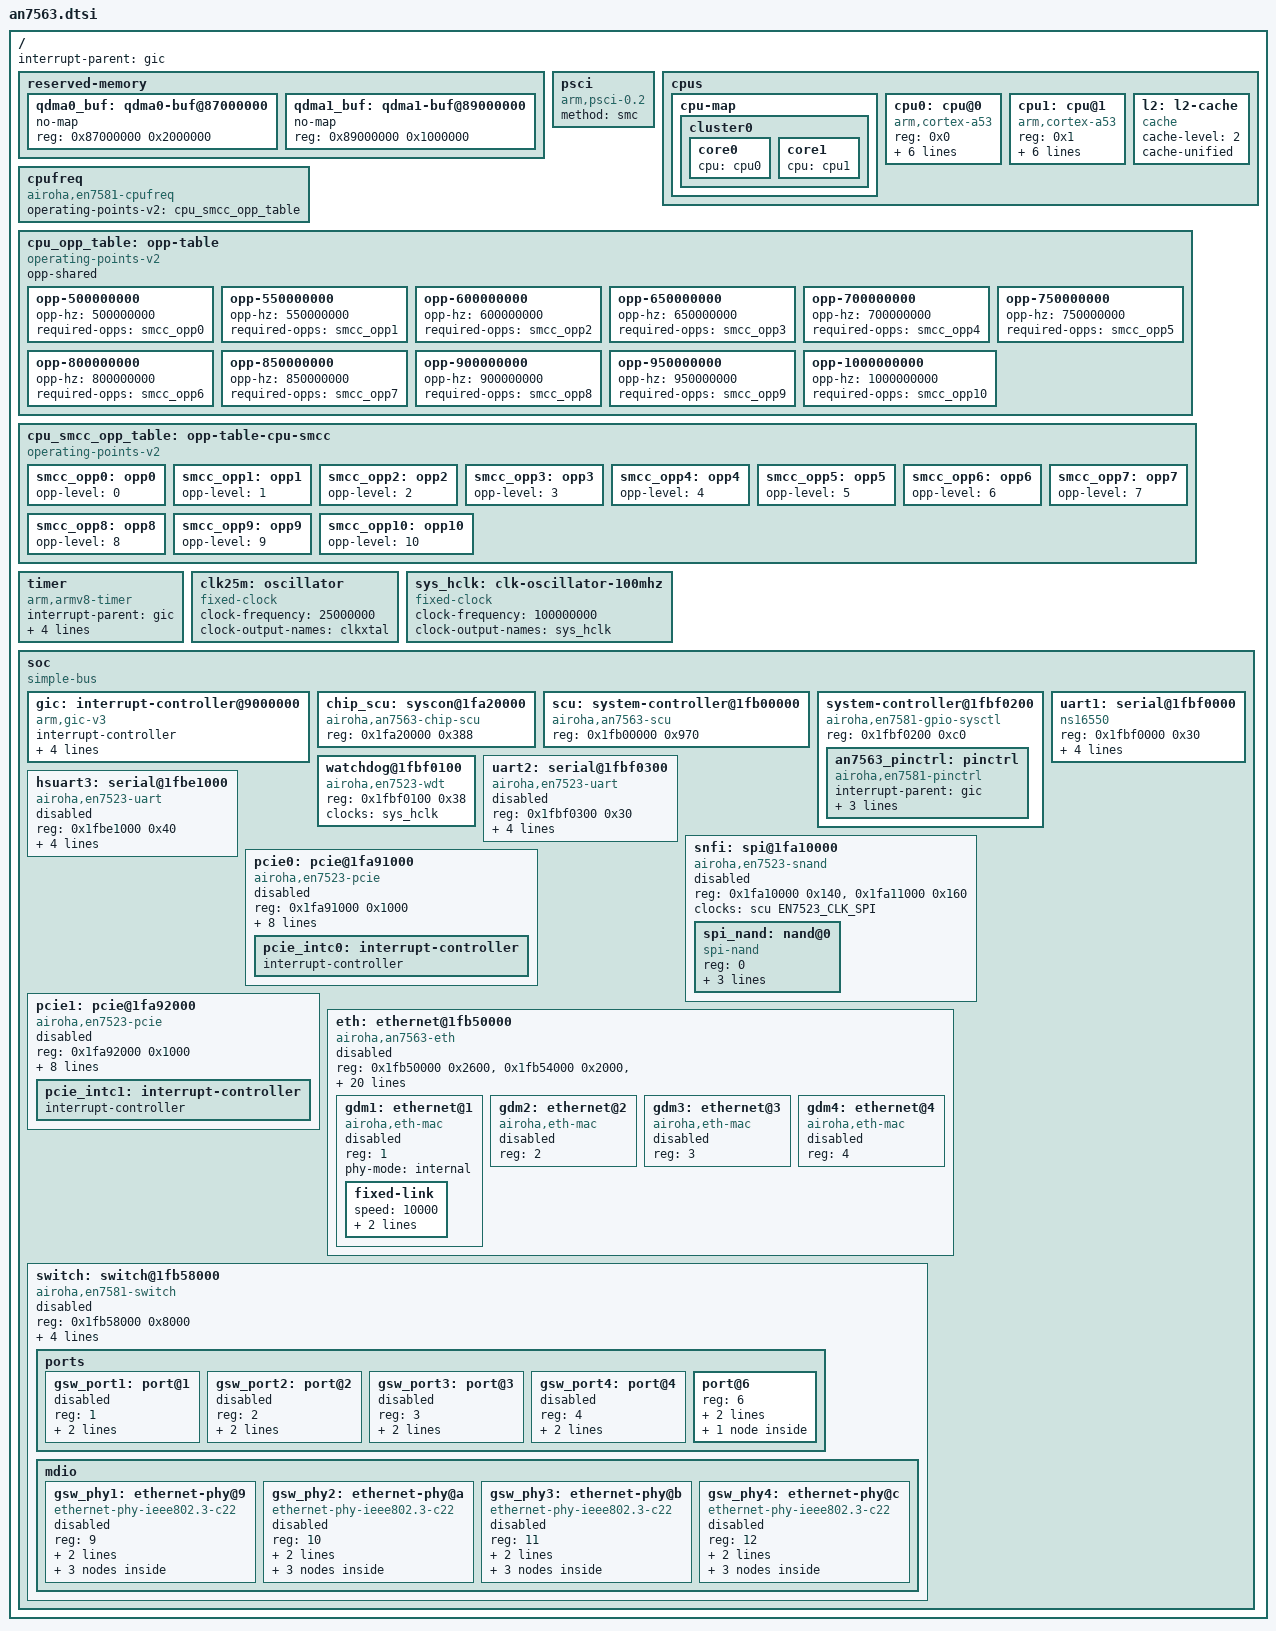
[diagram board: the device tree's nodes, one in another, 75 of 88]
// SPDX-License-Identifier: (GPL-2.0-only OR BSD-2-Clause)
/*
 * Airoha AN7563 / AN7552 SoC dtsi.
 *
 * AN7563 boots a dual Cortex-A53 cluster in 32-bit AArch32 mode, but
 * its chip-SCU and SCU register windows match the EN7581 layout (the
 * IOMUX_1 register sits at chip-SCU offset 0x214, not 0x210 as on
 * EN7523). To share clk-en7523 / reset / pinctrl-airoha driver paths
 * with EN7581, the SCU nodes carry an AN7563-specific compatible
 * followed by the "airoha,en7581-{chip-,}scu" fallback compatible.
 *
 * Naming caveat: vendor device-tree drops (e.g. Xiaomi BE5000's
 * en7563pt_xiaomi-be5000.dts and Netgear EXS27/EXS25/EXS18 GPL
 * en7523.dtsi) tag the root node with "econet,en7523" or
 * "airoha,en7523". That is a vendor naming artefact - the underlying
 * silicon is the EN7581 family (AN7563 is the 2-core AArch32 SKU of
 * the EN7581 IP set), and the Frame Engine / QDMA / GSW / SerDes /
 * chip-SCU register banks all match the EN7581 mainline definitions
 * verified against drivers/net/ethernet/airoha/airoha_eth.c and
 * drivers/clk/clk-en7523.c. Do NOT treat the vendor "en7523"
 * compatible as meaning "EN7523 family" - it does not.
 *
 * Verified against vendor DTS sources:
 *   - Netgear EXS27 V1.0.1.34 GPL drop (target/linux/airoha/files/
 *     arch/arm64/boot/dts/en7523.dtsi)
 *   - Xiaomi BE5000 official DTS (en7563pt_xiaomi-be5000.dts in
 *     the IOWRT Airoha collection drop)
 * Confirmed identical for: frame_engine reg / IRQs (SPI 37/55-57,
 * 38/58-60, 49, 64), GSW reg / IRQ (1fb58000 / SPI 31), chip-SCU
 * IOMUX layout (0x214..0x22C + 0x20C + 0x4C). Only the NPU sub-block
 * differs - AN7563 wires fewer IRQs than EN7581 (9 vs 15) and exposes
 * the extra 0x1e800000+0x60000 SRAM window, so the NPU node is
 * intentionally not declared here until airoha_npu gains AN7563
 * support (NPU_NUM_CORES is currently hardcoded 8).
 */

#include <dt-bindings/interrupt-controller/irq.h>
#include <dt-bindings/interrupt-controller/arm-gic.h>
#include <dt-bindings/clock/en7523-clk.h>
#include <dt-bindings/reset/airoha,en7581-reset.h>
#include <dt-bindings/leds/common.h>

/ {
	interrupt-parent = <&gic>;
	#address-cells = <1>;
	#size-cells = <1>;

	/*
	 * Reserve QDMA0 / QDMA1 hwfd buffer pools at fixed physical
	 * addresses so the airoha_eth driver can map them via
	 * memory-region. Vendor BL2/BL31 reserves the first 0x88000 of
	 * DRAM (see arch/arm/Makefile textofs=0x00088000); board DTS
	 * may further extend reserved-memory if a NPU firmware area or
	 * dying-gasp save region is added.
	 */
	reserved-memory {
		#address-cells = <1>;
		#size-cells = <1>;
		ranges;

		qdma0_buf: qdma0-buf@87000000 {
			no-map;
			reg = <0x87000000 0x2000000>;
		};

		qdma1_buf: qdma1-buf@89000000 {
			no-map;
			reg = <0x89000000 0x1000000>;
		};
	};

	psci {
		compatible = "arm,psci-0.2";
		method = "smc";
	};

	cpus {
		#address-cells = <1>;
		#size-cells = <0>;

		cpu-map {
			cluster0 {
				core0 {
					cpu = <&cpu0>;
				};

				core1 {
					cpu = <&cpu1>;
				};
			};
		};

		cpu0: cpu@0 {
			device_type = "cpu";
			compatible = "arm,cortex-a53";
			reg = <0x0>;
			enable-method = "psci";
			clock-frequency = <80000000>;
			next-level-cache = <&l2>;

			/*
			 * CPUFreq is driven by the airoha,en7581-cpufreq node
			 * below: ATF exposes an SMCCC AVS API which the
			 * airoha-cpu-pmdomain driver wraps as a PM domain +
			 * read-only clock; airoha-cpufreq then registers a
			 * cpufreq-dt device that walks the OPP v2 table.
			 */
			operating-points-v2 = <&cpu_opp_table>;
			clocks = <&cpufreq>;
			clock-names = "cpu";
			power-domains = <&cpufreq>;
			power-domain-names = "perf";
			#cooling-cells = <2>;
		};

		cpu1: cpu@1 {
			device_type = "cpu";
			compatible = "arm,cortex-a53";
			reg = <0x1>;
			enable-method = "psci";
			clock-frequency = <80000000>;
			next-level-cache = <&l2>;

			operating-points-v2 = <&cpu_opp_table>;
			clocks = <&cpufreq>;
			clock-names = "cpu";
			power-domains = <&cpufreq>;
			power-domain-names = "perf";
			#cooling-cells = <2>;
		};

		l2: l2-cache {
			compatible = "cache";
			cache-level = <2>;
			cache-unified;
		};
	};

	/*
	 * CPUFreq plumbing for AN7563. The driver model is the same
	 * one Lorenzo / Christian introduced for EN7581 in
	 * drivers/cpufreq/airoha-cpufreq.c + drivers/pmdomain/mediatek/
	 * airoha-cpu-pmdomain.c. AN7563 ATF exposes the same AVS_OP
	 * SMC handle (0x82000301, AIROHA_AVS_OP_FREQ_DYN_ADJ /
	 * AIROHA_AVS_OP_GET_FREQ), so the same compatible value works.
	 *
	 * Frequency / performance-level pairing is taken from the
	 * Xiaomi BE5000 vendor DTS (en7563pt_xiaomi-be5000.dts), which
	 * lists 500..1000 MHz in 50 MHz steps. AN7563 (AN7552 CPU SKU)
	 * does not expose the 1050..1200 MHz tier that EN7581's larger
	 * 4-core cluster supports, so the OPP table is truncated at
	 * level 10 to match silicon reality - boosting beyond that
	 * would otherwise cause the ATF AVS_OP_FREQ_DYN_ADJ SMC to
	 * silently clip and confuse the OPP framework.
	 */
	cpufreq: cpufreq {
		compatible = "airoha,en7581-cpufreq";

		operating-points-v2 = <&cpu_smcc_opp_table>;

		#power-domain-cells = <0>;
		#clock-cells = <0>;
	};

	cpu_opp_table: opp-table {
		compatible = "operating-points-v2";
		opp-shared;

		opp-500000000 {
			opp-hz = /bits/ 64 <500000000>;
			required-opps = <&smcc_opp0>;
		};

		opp-550000000 {
			opp-hz = /bits/ 64 <550000000>;
			required-opps = <&smcc_opp1>;
		};

		opp-600000000 {
			opp-hz = /bits/ 64 <600000000>;
			required-opps = <&smcc_opp2>;
		};

		opp-650000000 {
			opp-hz = /bits/ 64 <650000000>;
			required-opps = <&smcc_opp3>;
		};

		opp-700000000 {
			opp-hz = /bits/ 64 <700000000>;
			required-opps = <&smcc_opp4>;
		};

		opp-750000000 {
			opp-hz = /bits/ 64 <750000000>;
			required-opps = <&smcc_opp5>;
		};

		opp-800000000 {
			opp-hz = /bits/ 64 <800000000>;
			required-opps = <&smcc_opp6>;
		};

		opp-850000000 {
			opp-hz = /bits/ 64 <850000000>;
			required-opps = <&smcc_opp7>;
		};

		opp-900000000 {
			opp-hz = /bits/ 64 <900000000>;
			required-opps = <&smcc_opp8>;
		};

		opp-950000000 {
			opp-hz = /bits/ 64 <950000000>;
			required-opps = <&smcc_opp9>;
		};

		opp-1000000000 {
			opp-hz = /bits/ 64 <1000000000>;
			required-opps = <&smcc_opp10>;
		};
	};

	cpu_smcc_opp_table: opp-table-cpu-smcc {
		compatible = "operating-points-v2";

		smcc_opp0: opp0 {
			opp-level = <0>;
		};

		smcc_opp1: opp1 {
			opp-level = <1>;
		};

		smcc_opp2: opp2 {
			opp-level = <2>;
		};

		smcc_opp3: opp3 {
			opp-level = <3>;
		};

		smcc_opp4: opp4 {
			opp-level = <4>;
		};

		smcc_opp5: opp5 {
			opp-level = <5>;
		};

		smcc_opp6: opp6 {
			opp-level = <6>;
		};

		smcc_opp7: opp7 {
			opp-level = <7>;
		};

		smcc_opp8: opp8 {
			opp-level = <8>;
		};

		smcc_opp9: opp9 {
			opp-level = <9>;
		};

		smcc_opp10: opp10 {
			opp-level = <10>;
		};
	};

	timer {
		compatible = "arm,armv8-timer";
		interrupt-parent = <&gic>;
		interrupts = <GIC_PPI 13 IRQ_TYPE_LEVEL_LOW>,
			     <GIC_PPI 14 IRQ_TYPE_LEVEL_LOW>,
			     <GIC_PPI 11 IRQ_TYPE_LEVEL_LOW>,
			     <GIC_PPI 10 IRQ_TYPE_LEVEL_LOW>;
	};

	clk25m: oscillator {
		compatible = "fixed-clock";
		#clock-cells = <0>;
		clock-frequency = <25000000>;
		clock-output-names = "clkxtal";
	};

	sys_hclk: clk-oscillator-100mhz {
		compatible = "fixed-clock";
		#clock-cells = <0>;
		clock-frequency = <100000000>;
		clock-output-names = "sys_hclk";
	};

	soc {
		compatible = "simple-bus";
		#address-cells = <1>;
		#size-cells = <1>;
		ranges;

		gic: interrupt-controller@9000000 {
			compatible = "arm,gic-v3";
			interrupt-controller;
			#interrupt-cells = <3>;
			#address-cells = <1>;
			#size-cells = <1>;
			reg = <0x09000000 0x20000>,
			      <0x09080000 0x80000>,
			      <0x09400000 0x2000>,
			      <0x09500000 0x2000>,
			      <0x09600000 0x20000>;
			interrupts = <GIC_PPI 9 IRQ_TYPE_LEVEL_LOW>;
		};

		chip_scu: syscon@1fa20000 {
			compatible = "airoha,an7563-chip-scu",
				     "airoha,en7581-chip-scu", "syscon";
			reg = <0x1fa20000 0x388>;
		};

		scu: system-controller@1fb00000 {
			compatible = "airoha,an7563-scu",
				     "airoha,en7581-scu", "syscon";
			reg = <0x1fb00000 0x970>;

			#clock-cells = <1>;
			#reset-cells = <1>;
		};

		system-controller@1fbf0200 {
			compatible = "airoha,en7581-gpio-sysctl", "syscon",
				     "simple-mfd";
			reg = <0x1fbf0200 0xc0>;

			an7563_pinctrl: pinctrl {
				compatible = "airoha,en7581-pinctrl";

				interrupt-parent = <&gic>;
				interrupts = <GIC_SPI 26 IRQ_TYPE_LEVEL_HIGH>;

				gpio-controller;
				#gpio-cells = <2>;

				interrupt-controller;
				#interrupt-cells = <2>;
			};
		};

		uart1: serial@1fbf0000 {
			compatible = "ns16550";
			reg = <0x1fbf0000 0x30>;
			reg-io-width = <4>;
			reg-shift = <2>;
			interrupts = <GIC_SPI 18 IRQ_TYPE_LEVEL_HIGH>;
			clock-frequency = <1843200>;
		};

		watchdog@1fbf0100 {
			compatible = "airoha,en7523-wdt";
			reg = <0x1fbf0100 0x38>;

			clocks = <&sys_hclk>;
			clock-names = "bus";
		};

		uart2: serial@1fbf0300 {
			compatible = "airoha,en7523-uart";
			reg = <0x1fbf0300 0x30>;
			reg-io-width = <4>;
			reg-shift = <2>;
			interrupts = <GIC_SPI 32 IRQ_TYPE_LEVEL_HIGH>;
			clock-frequency = <7372800>;

			status = "disabled";
		};

		hsuart3: serial@1fbe1000 {
			compatible = "airoha,en7523-uart";
			reg = <0x1fbe1000 0x40>;
			reg-io-width = <4>;
			reg-shift = <2>;
			interrupts = <GIC_SPI 54 IRQ_TYPE_LEVEL_HIGH>;
			clock-frequency = <7372800>;

			status = "disabled";
		};

		snfi: spi@1fa10000 {
			compatible = "airoha,en7523-snand", "airoha,en7581-snand";
			reg = <0x1fa10000 0x140>,
			      <0x1fa11000 0x160>;

			clocks = <&scu EN7523_CLK_SPI>;
			clock-names = "spi";

			#address-cells = <1>;
			#size-cells = <0>;

			status = "disabled";

			spi_nand: nand@0 {
				compatible = "spi-nand";
				reg = <0>;
				spi-max-frequency = <50000000>;
				spi-tx-bus-width = <1>;
				spi-rx-bus-width = <2>;
			};
		};

		pcie0: pcie@1fa91000 {
			compatible = "airoha,en7523-pcie", "mediatek,mt7622-pcie";
			device_type = "pci";
			reg = <0x1fa91000 0x1000>;
			reg-names = "port0";
			linux,pci-domain = <0>;
			#address-cells = <3>;
			#size-cells = <2>;
			interrupts = <GIC_SPI 39 IRQ_TYPE_LEVEL_HIGH>;
			interrupt-names = "pcie_irq";
			clocks = <&scu EN7523_CLK_PCIE>;
			clock-names = "sys_ck0";
			bus-range = <0x00 0xff>;
			ranges = <0x82000000 0 0x20000000 0x20000000 0 0x2000000>;

			status = "disabled";

			#interrupt-cells = <1>;
			interrupt-map-mask = <0 0 0 7>;
			interrupt-map = <0 0 0 1 &pcie_intc0 0>,
					<0 0 0 2 &pcie_intc0 1>,
					<0 0 0 3 &pcie_intc0 2>,
					<0 0 0 4 &pcie_intc0 3>;

			pcie_intc0: interrupt-controller {
				interrupt-controller;
				#address-cells = <0>;
				#interrupt-cells = <1>;
			};
		};

		pcie1: pcie@1fa92000 {
			compatible = "airoha,en7523-pcie", "mediatek,mt7622-pcie";
			device_type = "pci";
			reg = <0x1fa92000 0x1000>;
			reg-names = "port1";
			linux,pci-domain = <1>;
			#address-cells = <3>;
			#size-cells = <2>;
			interrupts = <GIC_SPI 40 IRQ_TYPE_LEVEL_HIGH>;
			interrupt-names = "pcie_irq";
			clocks = <&scu EN7523_CLK_PCIE>;
			clock-names = "sys_ck1";
			bus-range = <0x00 0xff>;
			ranges = <0x82000000 0 0x22000000 0x22000000 0 0x2000000>;

			status = "disabled";

			#interrupt-cells = <1>;
			interrupt-map-mask = <0 0 0 7>;
			interrupt-map = <0 0 0 1 &pcie_intc1 0>,
					<0 0 0 2 &pcie_intc1 1>,
					<0 0 0 3 &pcie_intc1 2>,
					<0 0 0 4 &pcie_intc1 3>;

			pcie_intc1: interrupt-controller {
				interrupt-controller;
				#address-cells = <0>;
				#interrupt-cells = <1>;
			};
		};

		/*
		 * Frame Engine + PPE + QDMA0/QDMA1 block. Register layout
		 * is identical to EN7581 (see arch/arm64/boot/dts/airoha/
		 * en7581.dtsi in mainline), so we fall back to the
		 * "airoha,en7581-eth" binding consumed by
		 * drivers/net/ethernet/airoha/airoha_eth.c. AN7563 boards
		 * use the on-chip 5-port GSW (port 6 == GDM1) for LAN
		 * connectivity; XSI / HSGMII serdes are wired separately on
		 * AN7581 only and are intentionally not referenced here.
		 *
		 * GDM2/GDM3/GDM4 remain disabled by default since AN7563
		 * SKUs in this OpenWrt subtarget do not use the PCS path.
		 */
		eth: ethernet@1fb50000 {
			compatible = "airoha,an7563-eth", "airoha,en7581-eth";
			reg = <0x1fb50000 0x2600>,
			      <0x1fb54000 0x2000>,
			      <0x1fb56000 0x2000>;
			reg-names = "fe", "qdma0", "qdma1";

			/*
			 * The upstream airoha_eth driver (EN7581 path,
			 * see drivers/net/ethernet/airoha/airoha_eth.c
			 * en7581_xsi_rsts_names[] after patch 310-07) calls
			 * devm_reset_control_bulk_get_exclusive() for the
			 * xsi MAC reset quadruple ("hsi0-mac", "hsi1-mac",
			 * "hsi-mac", "xfp-mac") unconditionally, so all four
			 * must be wired even on AN7563 SKUs that do not
			 * connect any XSI / HSGMII / XFP serdes - otherwise
			 * probe fails with -ENOENT.
			 *
			 * AN7563 SCU re-uses the EN7581 reset bit layout
			 * (vendor ecnt_scu.c shares the TCSUPPORT_CPU_EN7581 |
			 * TCSUPPORT_CPU_AN7552 register table for these bits),
			 * so the EN7581_* reset IDs map to the correct bits
			 * via clk-en7523's en7581_rst_map.
			 */
			resets = <&scu EN7581_FE_RST>,
				 <&scu EN7581_FE_PDMA_RST>,
				 <&scu EN7581_FE_QDMA_RST>,
				 <&scu EN7581_DUAL_HSI0_MAC_RST>,
				 <&scu EN7581_DUAL_HSI1_MAC_RST>,
				 <&scu EN7581_HSI_MAC_RST>,
				 <&scu EN7581_XFP_MAC_RST>;
			reset-names = "fe", "pdma", "qdma",
				      "hsi0-mac", "hsi1-mac", "hsi-mac",
				      "xfp-mac";

			interrupts = <GIC_SPI 37 IRQ_TYPE_LEVEL_HIGH>,
				     <GIC_SPI 55 IRQ_TYPE_LEVEL_HIGH>,
				     <GIC_SPI 56 IRQ_TYPE_LEVEL_HIGH>,
				     <GIC_SPI 57 IRQ_TYPE_LEVEL_HIGH>,
				     <GIC_SPI 38 IRQ_TYPE_LEVEL_HIGH>,
				     <GIC_SPI 58 IRQ_TYPE_LEVEL_HIGH>,
				     <GIC_SPI 59 IRQ_TYPE_LEVEL_HIGH>,
				     <GIC_SPI 60 IRQ_TYPE_LEVEL_HIGH>,
				     <GIC_SPI 49 IRQ_TYPE_LEVEL_HIGH>,
				     <GIC_SPI 64 IRQ_TYPE_LEVEL_HIGH>;

			memory-region = <&qdma0_buf>, <&qdma1_buf>;
			memory-region-names = "qdma0-buf", "qdma1-buf";

			status = "disabled";

			#address-cells = <1>;
			#size-cells = <0>;

			gdm1: ethernet@1 {
				compatible = "airoha,eth-mac";
				reg = <1>;
				phy-mode = "internal";
				status = "disabled";

				fixed-link {
					speed = <10000>;
					full-duplex;
					pause;
				};
			};

			gdm2: ethernet@2 {
				compatible = "airoha,eth-mac";
				reg = <2>;
				status = "disabled";
			};

			gdm3: ethernet@3 {
				compatible = "airoha,eth-mac";
				reg = <3>;
				status = "disabled";
			};

			gdm4: ethernet@4 {
				compatible = "airoha,eth-mac";
				reg = <4>;
				status = "disabled";
			};
		};

		/*
		 * 5-port internal Gigabit Switch. Bound to the eth GDM1
		 * port through cpu port 6, with 4 user-facing internal
		 * GE PHYs at MDIO addresses 9..12. Re-uses the EN7581
		 * mt7530 DSA driver path (drivers/net/dsa/mt7530.c).
		 */
		switch: switch@1fb58000 {
			compatible = "airoha,en7581-switch";
			reg = <0x1fb58000 0x8000>;
			resets = <&scu EN7581_GSW_RST>;

			interrupt-controller;
			#interrupt-cells = <1>;
			interrupt-parent = <&gic>;
			interrupts = <GIC_SPI 31 IRQ_TYPE_LEVEL_HIGH>;

			status = "disabled";

			#address-cells = <1>;
			#size-cells = <1>;

			ports {
				#address-cells = <1>;
				#size-cells = <0>;

				gsw_port1: port@1 {
					reg = <1>;
					phy-mode = "internal";
					phy-handle = <&gsw_phy1>;
					status = "disabled";
				};

				gsw_port2: port@2 {
					reg = <2>;
					phy-mode = "internal";
					phy-handle = <&gsw_phy2>;
					status = "disabled";
				};

				gsw_port3: port@3 {
					reg = <3>;
					phy-mode = "internal";
					phy-handle = <&gsw_phy3>;
					status = "disabled";
				};

				gsw_port4: port@4 {
					reg = <4>;
					phy-mode = "internal";
					phy-handle = <&gsw_phy4>;
					status = "disabled";
				};

				port@6 {
					reg = <6>;
					ethernet = <&gdm1>;
					phy-mode = "internal";

					fixed-link {
						speed = <10000>;
						full-duplex;
						pause;
					};
				};
			};

			mdio: mdio {
				#address-cells = <1>;
				#size-cells = <0>;

				gsw_phy1: ethernet-phy@9 {
					compatible = "ethernet-phy-ieee802.3-c22";
					reg = <9>;
					interrupts = <1>;
					phy-mode = "internal";
					status = "disabled";

					leds {
						#address-cells = <1>;
						#size-cells = <0>;

						gsw_phy1_led0: led@0 {
							reg = <0>;
							status = "disabled";
						};

						gsw_phy1_led1: led@1 {
							reg = <1>;
							status = "disabled";
						};
					};
				};

				gsw_phy2: ethernet-phy@a {
					compatible = "ethernet-phy-ieee802.3-c22";
					reg = <10>;
					interrupts = <2>;
					phy-mode = "internal";
					status = "disabled";

					leds {
						#address-cells = <1>;
						#size-cells = <0>;

						gsw_phy2_led0: led@0 {
							reg = <0>;
							status = "disabled";
						};

						gsw_phy2_led1: led@1 {
							reg = <1>;
							status = "disabled";
						};
					};
				};

				gsw_phy3: ethernet-phy@b {
					compatible = "ethernet-phy-ieee802.3-c22";
					reg = <11>;
					interrupts = <3>;
					phy-mode = "internal";
					status = "disabled";

					leds {
						#address-cells = <1>;
						#size-cells = <0>;

						gsw_phy3_led0: led@0 {
							reg = <0>;
							status = "disabled";
						};

						gsw_phy3_led1: led@1 {
							reg = <1>;
							status = "disabled";
						};
					};
				};

				gsw_phy4: ethernet-phy@c {
					compatible = "ethernet-phy-ieee802.3-c22";
					reg = <12>;
					interrupts = <4>;
					phy-mode = "internal";
					status = "disabled";

					leds {
						#address-cells = <1>;
						#size-cells = <0>;

						gsw_phy4_led0: led@0 {
							reg = <0>;
							status = "disabled";
						};

						gsw_phy4_led1: led@1 {
							reg = <1>;
							status = "disabled";
						};
					};
				};
			};
		};
	};
};
